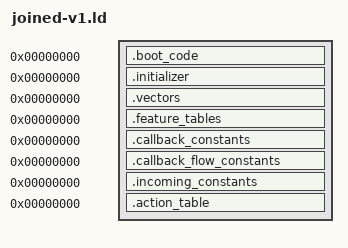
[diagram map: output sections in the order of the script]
OUTPUT_ARCH(riscv)
SECTIONS
{
 .boot_code 0 : SUBALIGN(2) { *(.boot_code)
  *(.text.tsl9_registered_callbacks_provider_10dcc)
  *(.text.tsl9_record_dispatch_block_10dde)
  *(.text.tsl9_record_dispatch_block_10de8)
  *(.text.tsl9_record_dispatch_block_10df6)
  *(.text.tsl9_record_dispatch_block_10dfc)
  *(.text.tsl9_record_dispatch_block_10e0c)
  *(.text.tsl9_record_dispatch_block_10e12)
  *(.text.tsl9_record_dispatch_block_10e20)
  *(.text.tsl9_record_dispatch_block_10e32)
  *(.text.tsl9_record_dispatch_block_10e34)
  *(.text.tsl9_record_dispatch_block_10e3c)
  *(.text.tsl9_record_dispatch_block_10e4a)
  *(.text.tsl9_record_dispatch_block_10e6a)
  *(.text.tsl9_record_dispatch_block_10e6c)
  *(.text.tsl9_callback_dependencies_provider_13eb4)
  *(.text.tsl9_record_dispatch_block_13eb6)
  *(.text.tsl9_record_dispatch_block_13edc)
  *(.text.tsl9_record_dispatch_block_13eea)
  *(.text.tsl9_record_dispatch_block_13ef4)
  *(.text.tsl9_record_dispatch_block_13efe)
  *(.text.tsl9_record_dispatch_block_13f10)
  *(.text.tsl9_record_dispatch_block_13f14)
  *(.text.tsl9_record_dispatch_block_13f30)
  *(.text.tsl9_record_dispatch_block_13f34)
  *(.text.tsl9_callback_dependencies_provider_155d0)
  *(.text.tsl9_record_dispatch_block_155e8)
  *(.text.tsl9_record_dispatch_block_155f6)
  *(.text.tsl9_record_dispatch_block_155fc)
  *(.text.tsl9_record_dispatch_block_1560e)
  *(.text.tsl9_record_dispatch_block_1561e)
  *(.text.tsl9_record_dispatch_block_15630)
  *(.text.tsl9_record_dispatch_block_1563c)
  *(.text.tsl9_record_dispatch_block_15650)
  *(.text.tsl9_record_dispatch_block_15666)
  *(.text.tsl9_record_dispatch_block_1567c)
  *(.text.tsl9_record_dispatch_block_15694)
  *(.text.tsl9_record_dispatch_block_156ac)
  *(.text.tsl9_record_dispatch_block_156c2)
  *(.text.tsl9_record_dispatch_block_156d8)
  *(.text.tsl9_record_dispatch_block_156f0)
  *(.text.tsl9_record_dispatch_block_15706)
  *(.text.tsl9_record_dispatch_block_15714)
  *(.text.tsl9_record_dispatch_block_15724)
  *(.text.tsl9_record_dispatch_block_15734)
  *(.text.tsl9_record_dispatch_block_15744)
  *(.text.tsl9_record_dispatch_block_15754)
  *(.text.tsl9_record_dispatch_block_1576a)
  *(.text.tsl9_record_dispatch_block_15774)
  *(.text.tsl9_record_dispatch_block_15786)
  *(.text.tsl9_record_dispatch_block_1578a)
  *(.text.tsl9_record_dispatch_block_1578c)
  *(.text.tsl9_record_dispatch_block_15798)
  *(.text.tsl9_record_dispatch_block_157aa)
  *(.text.tsl9_record_dispatch_block_157b4)
  *(.text.tsl9_record_dispatch_block_157b8)
  *(.text.tsl9_record_dispatch_block_157d0)
  *(.text.tsl9_record_dispatch_block_157d4)
  *(.text.tsl9_record_dispatch_block_157d6)
  *(.text.tsl9_record_dispatch_block_157d8)
  *(.text.tsl9_record_dispatch_block_157dc)
  *(.text.tsl9_record_dispatch_block_157f2)
  *(.text.tsl9_record_dispatch_block_157f6)
  *(.text.tsl9_record_dispatch_block_157f8)
  *(.text.tsl9_record_dispatch_block_15808)
  *(.text.tsl9_record_dispatch_block_1580c)
  *(.text.tsl9_record_dispatch_block_1580e)
  *(.text.tsl9_record_dispatch_block_1581e)
  *(.text.tsl9_record_dispatch_block_1582c)
  *(.text.tsl9_record_dispatch_block_15830)
  *(.text.tsl9_record_dispatch_block_15846)
  *(.text.tsl9_record_dispatch_block_15854)
  *(.text.tsl9_record_dispatch_block_15864)
  *(.text.tsl9_record_dispatch_block_15874)
  *(.text.tsl9_record_dispatch_block_15884)
  *(.text.tsl9_record_dispatch_block_15888)
  *(.text.tsl9_record_dispatch_block_1589e)
  *(.text.tsl9_record_dispatch_block_158a2)
  *(.text.tsl9_record_dispatch_block_158b8)
  *(.text.tsl9_record_dispatch_block_158c8)
  *(.text.tsl9_record_dispatch_block_158d8)
  *(.text.tsl9_record_dispatch_block_158dc)
  *(.text.tsl9_record_dispatch_block_158f2)
  *(.text.tsl9_record_dispatch_block_15902)
  *(.text.tsl9_record_dispatch_block_15912)
  *(.text.tsl9_record_dispatch_block_15920)
  *(.text.tsl9_record_dispatch_block_1592e)
  *(.text.tsl9_record_dispatch_block_1593c)
  *(.text.tsl9_record_dispatch_block_15940)
  *(.text.tsl9_record_dispatch_block_15956)
  *(.text.tsl9_record_dispatch_block_1595a)
  *(.text.tsl9_record_dispatch_block_15970)
  *(.text.tsl9_record_dispatch_block_15980)
  *(.text.tsl9_record_dispatch_block_15990)
  *(.text.tsl9_record_dispatch_block_159a2)
  *(.text.tsl9_record_dispatch_block_159b4)
  *(.text.tsl9_record_dispatch_block_159c6)
  *(.text.tsl9_record_dispatch_block_159d8)
  *(.text.tsl9_record_dispatch_block_159ea)
  *(.text.tsl9_record_dispatch_block_159fc)
  *(.text.tsl9_record_dispatch_block_15a0e)
  *(.text.tsl9_record_dispatch_block_15a20)
  *(.text.tsl9_record_dispatch_block_15a32)
  *(.text.tsl9_record_dispatch_block_15a44)
  *(.text.tsl9_record_dispatch_block_15a48)
  *(.text.tsl9_record_dispatch_block_15a60)
  *(.text.tsl9_record_dispatch_block_15a72)
  *(.text.tsl9_record_dispatch_block_15a84)
  *(.text.tsl9_record_dispatch_block_15a88)
  *(.text.tsl9_record_dispatch_block_15a9c)
  *(.text.tsl9_record_dispatch_block_15aac)
  *(.text.tsl9_record_dispatch_block_15abc)
  *(.text.tsl9_record_dispatch_block_15acc)
  *(.text.tsl9_record_dispatch_block_15ace)
  *(.text.tsl9_record_dispatch_block_15adc)
  *(.text.tsl9_record_dispatch_block_15aea)
  *(.text.tsl9_record_dispatch_block_15aee)
  *(.text.tsl9_record_dispatch_block_15afe)
  *(.text.tsl9_record_dispatch_block_15b0c)
  *(.text.tsl9_record_dispatch_block_15b0e)
  *(.text.tsl9_record_dispatch_block_15b16)
  *(.text.tsl9_record_dispatch_block_15b24)
  *(.text.tsl9_record_dispatch_block_15b3a)
  *(.text.tsl9_record_dispatch_block_15b3c)
  *(.text.tsl9_record_dispatch_block_15b56)
  *(.text.tsl9_record_dispatch_block_15b5a)
  *(.text.tsl9_record_dispatch_block_15b70)
  *(.text.tsl9_record_dispatch_block_15b80)
  *(.text.tsl9_record_dispatch_block_15b90)
  *(.text.tsl9_record_dispatch_block_15b94)
  *(.text.tsl9_record_dispatch_block_15baa)
  *(.text.tsl9_record_dispatch_block_15bba)
  *(.text.tsl9_record_dispatch_block_15bca)
  *(.text.tsl9_record_dispatch_block_15bde)
  *(.text.tsl9_record_dispatch_block_15bf2)
  *(.text.tsl9_record_dispatch_block_15c02)
  *(.text.tsl9_record_dispatch_block_15c12)
  *(.text.tsl9_record_dispatch_block_15c26)
  *(.text.tsl9_record_dispatch_block_15c3a)
  *(.text.tsl9_record_dispatch_block_15c4a)
  *(.text.tsl9_record_dispatch_block_15c64)
  *(.text.tsl9_record_dispatch_block_15c68)
  *(.text.tsl9_record_dispatch_block_15c7e)
  *(.text.tsl9_record_dispatch_block_15c82)
  *(.text.tsl9_record_dispatch_block_15c9a)
  *(.text.tsl9_record_dispatch_block_15c9e)
  *(.text.tsl9_record_dispatch_block_15cb6)
  *(.text.tsl9_record_dispatch_block_15cba)
  *(.text.tsl9_record_dispatch_block_15cd2)
  *(.text.tsl9_record_dispatch_block_15cd6)
  *(.text.tsl9_record_dispatch_block_15cee)
  *(.text.tsl9_record_dispatch_block_15cf2)
  *(.text.tsl9_record_dispatch_block_15d0a)
  *(.text.tsl9_record_dispatch_block_15d0e)
  *(.text.tsl9_record_dispatch_block_15d26)
  *(.text.tsl9_record_dispatch_block_15d38)
  *(.text.tsl9_record_dispatch_block_15d4a)
  *(.text.tsl9_record_dispatch_block_15d58)
  *(.text.tsl9_record_dispatch_block_15d68)
  *(.text.tsl9_record_dispatch_block_15d78)
  *(.text.tsl9_record_dispatch_block_15d88)
  *(.text.tsl9_record_dispatch_block_15d8c)
  *(.text.tsl9_record_dispatch_block_15d94)
  *(.text.tsl9_record_dispatch_block_15d96)
  *(.text.tsl9_record_dispatch_block_15da6)
  *(.text.tsl9_record_dispatch_block_15db6)
  *(.text.tsl9_record_dispatch_block_15dc6)
  *(.text.tsl9_record_dispatch_block_15dd8)
  *(.text.tsl9_record_dispatch_block_15dea)
  *(.text.tsl9_record_dispatch_block_15dfc)
  *(.text.tsl9_record_dispatch_block_15e0e)
  *(.text.tsl9_record_dispatch_block_15e20)
  *(.text.tsl9_record_dispatch_block_15e24)
  *(.text.tsl9_record_dispatch_block_15e3a)
  *(.text.tsl9_record_dispatch_block_15e4a)
  *(.text.tsl9_record_dispatch_block_15e5a)
  *(.text.tsl9_record_dispatch_block_15e5e)
  *(.text.tsl9_record_dispatch_block_15e74)
  *(.text.tsl9_record_dispatch_block_15e84)
  *(.text.tsl9_record_dispatch_block_15e94)
  *(.text.tsl9_record_dispatch_block_15ea4)
  *(.text.tsl9_record_dispatch_block_15eb4)
  *(.text.tsl9_record_dispatch_block_15ec2)
  *(.text.tsl9_record_dispatch_block_15ed2)
  *(.text.tsl9_record_dispatch_block_15ee2)
  *(.text.tsl9_record_dispatch_block_15ef2)
  *(.text.tsl9_record_dispatch_block_15f02)
  *(.text.tsl9_record_dispatch_block_15f12)
  *(.text.tsl9_record_dispatch_block_15f22)
  *(.text.tsl9_record_dispatch_block_15f32)
  *(.text.tsl9_record_dispatch_block_15f42)
  *(.text.tsl9_record_dispatch_block_15f52)
  *(.text.tsl9_record_dispatch_block_15f62)
  *(.text.tsl9_record_dispatch_block_15f72)
  *(.text.tsl9_record_dispatch_block_15f82)
  *(.text.tsl9_record_dispatch_block_15f92)
  *(.text.tsl9_record_dispatch_block_15fa2)
  *(.text.tsl9_record_dispatch_block_15fa6)
  *(.text.tsl9_record_dispatch_block_15fbc)
  *(.text.tsl9_record_dispatch_block_15fcc)
  *(.text.tsl9_record_dispatch_block_15fdc)
  *(.text.tsl9_record_dispatch_block_15fea)
  *(.text.tsl9_record_dispatch_block_15ffa)
  *(.text.tsl9_record_dispatch_block_1600a)
  *(.text.tsl9_record_dispatch_block_1601a)
  *(.text.tsl9_record_dispatch_block_1602a)
  *(.text.tsl9_record_dispatch_block_1603a)
  *(.text.tsl9_record_dispatch_block_1605a)
  *(.text.tsl9_record_dispatch_block_1606a)
  *(.text.tsl9_record_dispatch_block_1607a)
  *(.text.tsl9_record_dispatch_block_1608a)
  *(.text.tsl9_record_dispatch_block_1609a)
  *(.text.tsl9_record_dispatch_block_1609e)
  *(.text.tsl9_record_dispatch_block_160b4)
  *(.text.tsl9_record_dispatch_block_160c4)
  *(.text.tsl9_record_dispatch_block_160d4)
  *(.text.tsl9_record_dispatch_block_160e4)
  *(.text.tsl9_record_dispatch_block_160f4)
  *(.text.tsl9_record_dispatch_block_16104)
  *(.text.tsl9_record_dispatch_block_16114)
  *(.text.tsl9_record_dispatch_block_16118)
  *(.text.tsl9_record_dispatch_block_1612e)
  *(.text.tsl9_record_dispatch_block_16132)
  *(.text.tsl9_record_dispatch_block_16148)
  *(.text.tsl9_record_dispatch_block_1614c)
  *(.text.tsl9_record_dispatch_block_16162)
  *(.text.tsl9_record_dispatch_block_16172)
  *(.text.tsl9_record_dispatch_block_16182)
  *(.text.tsl9_record_dispatch_block_16192)
  *(.text.tsl9_record_dispatch_block_161a2)
  *(.text.tsl9_record_dispatch_block_161b0)
  *(.text.tsl9_record_dispatch_block_161c0)
  *(.text.tsl9_record_dispatch_block_161ce)
  *(.text.tsl9_record_dispatch_block_161e0)
  *(.text.tsl9_record_dispatch_block_161f6)
  *(.text.tsl9_record_dispatch_block_16206)
  *(.text.tsl9_record_dispatch_block_16216)
  *(.text.tsl9_record_dispatch_block_16226)
  *(.text.tsl9_record_dispatch_block_16236)
  *(.text.tsl9_record_dispatch_block_16246)
  *(.text.tsl9_record_dispatch_block_16256)
  *(.text.tsl9_record_dispatch_block_16266)
  *(.text.tsl9_record_dispatch_block_16276)
  *(.text.tsl9_record_dispatch_block_16286)
  *(.text.tsl9_record_dispatch_block_16296)
  *(.text.tsl9_record_dispatch_block_162ac)
  *(.text.tsl9_record_dispatch_block_162be)
  *(.text.tsl9_record_dispatch_block_162d2)
  *(.text.tsl9_record_dispatch_block_162e6)
  *(.text.tsl9_record_dispatch_block_162fe)
  *(.text.tsl9_record_dispatch_block_16304)
  *(.text.tsl9_record_dispatch_block_16318)
  *(.text.tsl9_record_dispatch_block_1631e)
  *(.text.tsl9_record_dispatch_block_16332)
  *(.text.tsl9_record_dispatch_block_16338)
  *(.text.tsl9_record_dispatch_block_1634c)
  *(.text.tsl9_record_dispatch_block_16368)
  *(.text.tsl9_record_dispatch_block_16378)
  *(.text.tsl9_record_dispatch_block_16388)
  *(.text.tsl9_record_dispatch_block_1638e)
  *(.text.tsl9_callback_dependencies_provider_16b50)
  *(.text.tsl9_record_dispatch_block_16b76)
 }
 .initializer 0 : SUBALIGN(4) { *(.initializer) }
 .vectors 0 : SUBALIGN(4) { *(.vectors) }
 .feature_tables 0 : SUBALIGN(4) { *(.feature_tables) }
 .callback_constants 0 : SUBALIGN(4) { *(.callback_constants) }
 .callback_flow_constants 0 : SUBALIGN(4) { *(.callback_flow_constants) }
 .incoming_constants 0 : SUBALIGN(4) { *(.incoming_constants) }
 .action_table 0 : SUBALIGN(4) { *(.rodata.tsl9_record_dispatch_table_1a6f4) }
 /DISCARD/ : { *(.comment) *(.riscv.attributes) *(.llvm_addrsig) }
}
